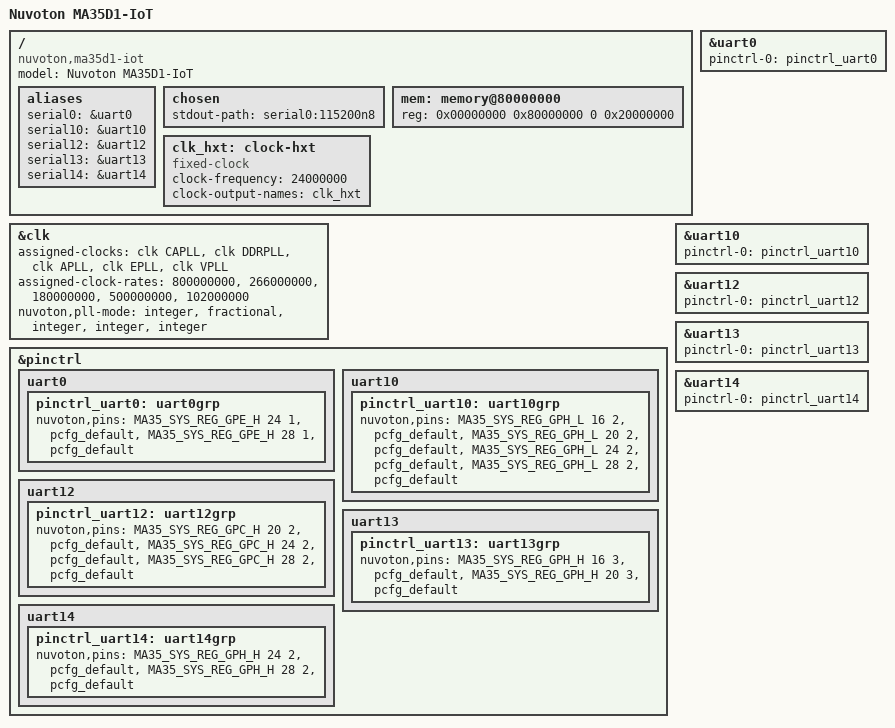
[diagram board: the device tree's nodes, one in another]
// SPDX-License-Identifier: GPL-2.0
/*
 * Copyright (C) 2023 Nuvoton Technology Corp.
 * Author: Shan-Chun Hung <schung@nuvoton.com>
 *         Jacky huang <ychuang3@nuvoton.com>
 */

/dts-v1/;
#include "ma35d1.dtsi"

/ {
	model = "Nuvoton MA35D1-IoT";
	compatible = "nuvoton,ma35d1-iot", "nuvoton,ma35d1";

	aliases {
		serial0 = &uart0;
		serial10 = &uart10;
		serial12 = &uart12;
		serial13 = &uart13;
		serial14 = &uart14;
	};

	chosen {
		stdout-path = "serial0:115200n8";
	};

	mem: memory@80000000 {
		device_type = "memory";
		reg = <0x00000000 0x80000000 0 0x20000000>; /* 512M DRAM */
	};

	clk_hxt: clock-hxt {
		compatible = "fixed-clock";
		#clock-cells = <0>;
		clock-frequency = <24000000>;
		clock-output-names = "clk_hxt";
	};
};

&clk {
	assigned-clocks = <&clk CAPLL>,
			  <&clk DDRPLL>,
			  <&clk APLL>,
			  <&clk EPLL>,
			  <&clk VPLL>;
	assigned-clock-rates = <800000000>,
			       <266000000>,
			       <180000000>,
			       <500000000>,
			       <102000000>;
	nuvoton,pll-mode = "integer",
			   "fractional",
			   "integer",
			   "integer",
			   "integer";
};

&pinctrl {
	uart0 {
		pinctrl_uart0: uart0grp {
			nuvoton,pins =
				<MA35_SYS_REG_GPE_H 24 1 &pcfg_default>,
				<MA35_SYS_REG_GPE_H 28 1 &pcfg_default>;
		};
	};

	uart10 {
		pinctrl_uart10: uart10grp {
			nuvoton,pins =
				<MA35_SYS_REG_GPH_L 16 2 &pcfg_default>,
				<MA35_SYS_REG_GPH_L 20 2 &pcfg_default>,
				<MA35_SYS_REG_GPH_L 24 2 &pcfg_default>,
				<MA35_SYS_REG_GPH_L 28 2 &pcfg_default>;
		};
	};

	uart12 {
		pinctrl_uart12: uart12grp {
			nuvoton,pins =
				<MA35_SYS_REG_GPC_H 20 2 &pcfg_default>,
				<MA35_SYS_REG_GPC_H 24 2 &pcfg_default>,
				<MA35_SYS_REG_GPC_H 28 2 &pcfg_default>;
		};
	};

	uart13 {
		pinctrl_uart13: uart13grp {
			nuvoton,pins =
				<MA35_SYS_REG_GPH_H 16 3 &pcfg_default>,
				<MA35_SYS_REG_GPH_H 20 3 &pcfg_default>;
		};
	};

	uart14 {
		pinctrl_uart14: uart14grp {
			nuvoton,pins =
				<MA35_SYS_REG_GPH_H 24 2 &pcfg_default>,
				<MA35_SYS_REG_GPH_H 28 2 &pcfg_default>;
		};
	};
};

&uart0 {
	pinctrl-names = "default";
	pinctrl-0 = <&pinctrl_uart0>;
	status = "okay";
};

&uart10 {
	pinctrl-names = "default";
	pinctrl-0 = <&pinctrl_uart10>;
	status = "okay";
};

&uart12 {
	pinctrl-names = "default";
	pinctrl-0 = <&pinctrl_uart12>;
	status = "okay";
};

&uart13 {
	pinctrl-names = "default";
	pinctrl-0 = <&pinctrl_uart13>;
	status = "okay";
};

&uart14 {
	pinctrl-names = "default";
	pinctrl-0 = <&pinctrl_uart14>;
	status = "okay";
};
